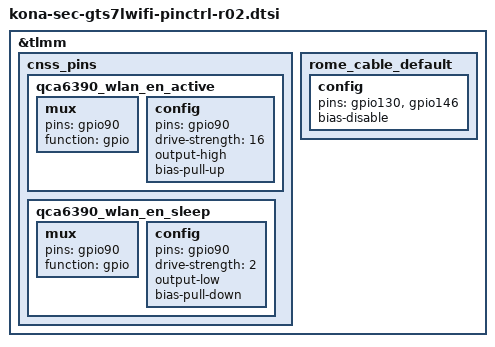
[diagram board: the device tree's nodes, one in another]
/* Copyright (c) 2020, The Linux Foundation. All rights reserved.
 *
 * This program is free software; you can redistribute it and/or modify
 * it under the terms of the GNU General Public License version 2 and
 * only version 2 as published by the Free Software Foundation.
 *
 * This program is distributed in the hope that it will be useful,
 * but WITHOUT ANY WARRANTY; without even the implied warranty of
 * MERCHANTABILITY or FITNESS FOR A PARTICULAR PURPOSE.  See the
 * GNU General Public License for more details.
 */
#include "../drivers/audio_gts7xl_pinctrl_common.dtsi"
#include "../drivers/kona-sec-gts7xl-camera-sensor-pinctrl-r01.dtsi"
#include "../drivers/kona-sec-gts7l-input-pinctrl.dtsi"
#include "../drivers/kona-sec-gts7l-grip-pinctrl-r00.dtsi"

&tlmm {
	cnss_pins {
            qca6390_wlan_en_active: qca6390_wlan_en_active {
                mux {
                    pins = "gpio90";
                    function = "gpio";
                };

                config {
                        pins = "gpio90";
                        drive-strength = <16>;
                        output-high;
                        bias-pull-up;
                };
            };

            qca6390_wlan_en_sleep: qca6390_wlan_en_sleep {
                mux {
                    pins = "gpio90";
                    function = "gpio";
                };

                config {
                    pins = "gpio90";
                    drive-strength = <2>;
                    output-low;
                    bias-pull-down;
                };
            };
    };
	rome_cable_default: rome_cable_default {
		config {
			pins = "gpio130","gpio146";
			bias-disable;
		};
	};
};
